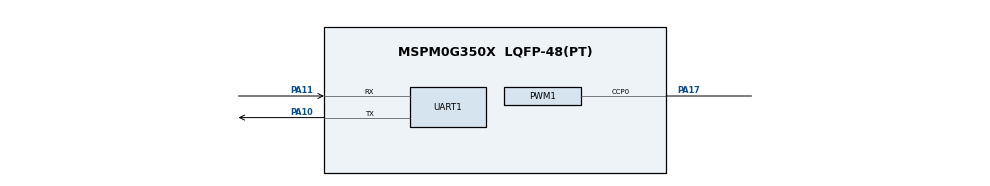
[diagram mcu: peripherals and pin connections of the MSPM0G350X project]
/**
 * @cliArgs --device "MSPM0G350X" --part "Default" --package "LQFP-48(PT)" --product "mspm0_sdk@2.10.00.04"
 * @versions {"tool":"1.27.1+4634"}
 */

/**
 * Import the modules used in this configuration.
 */
const GPIO   = scripting.addModule("/ti/driverlib/GPIO", {}, false);
const GPIO1  = GPIO.addInstance();
const GPIO3  = GPIO.addInstance();
const PWM    = scripting.addModule("/ti/driverlib/PWM", {}, false);
const PWM1   = PWM.addInstance();
const SYSCTL = scripting.addModule("/ti/driverlib/SYSCTL");
const UART   = scripting.addModule("/ti/driverlib/UART", {}, false);
const UART1  = UART.addInstance();

/**
 * Write custom configuration values to the imported modules.
 */
const gate7  = system.clockTree["MFCLKGATE"];
gate7.enable = true;

GPIO1.$name                          = "TB6612";
GPIO1.associatedPins.create(4);
GPIO1.associatedPins[0].$name        = "AIN1";
GPIO1.associatedPins[0].initialValue = "SET";
GPIO1.associatedPins[0].assignedPort = "PORTB";
GPIO1.associatedPins[0].assignedPin  = "18";
GPIO1.associatedPins[1].$name        = "AIN2";
GPIO1.associatedPins[1].initialValue = "SET";
GPIO1.associatedPins[1].assignedPort = "PORTA";
GPIO1.associatedPins[1].assignedPin  = "18 ";
GPIO1.associatedPins[2].$name        = "BIN1";
GPIO1.associatedPins[2].initialValue = "SET";
GPIO1.associatedPins[2].assignedPort = "PORTA";
GPIO1.associatedPins[2].assignedPin  = "12";
GPIO1.associatedPins[3].$name        = "BIN2";
GPIO1.associatedPins[3].initialValue = "SET";
GPIO1.associatedPins[3].assignedPort = "PORTA";
GPIO1.associatedPins[3].assignedPin  = "13";

const Board = scripting.addModule("/ti/driverlib/Board", {}, false);

GPIO3.$name                          = "OLED";
GPIO3.associatedPins.create(2);
GPIO3.associatedPins[0].$name        = "OLED_SCL";
GPIO3.associatedPins[0].initialValue = "SET";
GPIO3.associatedPins[0].assignedPort = "PORTB";
GPIO3.associatedPins[0].assignedPin  = "2";
GPIO3.associatedPins[1].initialValue = "SET";
GPIO3.associatedPins[1].assignedPort = "PORTB";
GPIO3.associatedPins[1].assignedPin  = "3";
GPIO3.associatedPins[1].$name        = "OLED_SDA";

PWM1.$name                      = "PWM_0";
PWM1.clockDivider               = 8;
PWM1.timerStartTimer            = true;
PWM1.peripheral.$assign         = "TIMA1";
PWM1.peripheral.ccp0Pin.$assign = "PA17";
PWM1.PWM_CHANNEL_0.$name        = "ti_driverlib_pwm_PWMTimerCC0";
PWM1.PWM_CHANNEL_0.invert       = true;
PWM1.PWM_CHANNEL_1.$name        = "ti_driverlib_pwm_PWMTimerCC1";
PWM1.PWM_CHANNEL_1.invert       = true;
PWM1.ccp0PinConfig.$name        = "ti_driverlib_gpio_GPIOPinGeneric0";
PWM1.ccp1PinConfig.$name        = "ti_driverlib_gpio_GPIOPinGeneric1";

SYSCTL.forceDefaultClkConfig = true;
SYSCTL.clockTreeEn           = true;

UART1.$name                    = "UART_0";
UART1.uartClkSrc               = "MFCLK";
UART1.enabledInterrupts        = ["RX"];
UART1.peripheral.$assign       = "UART0";
UART1.peripheral.rxPin.$assign = "PA11";
UART1.peripheral.txPin.$assign = "PA10";
UART1.txPinConfig.$name        = "ti_driverlib_gpio_GPIOPinGeneric4";
UART1.rxPinConfig.$name        = "ti_driverlib_gpio_GPIOPinGeneric5";

const ProjectConfig              = scripting.addModule("/ti/project_config/ProjectConfig", {}, false);
ProjectConfig.migrationCondition = true;

/**
 * Pinmux solution for unlocked pins/peripherals. This ensures that minor changes to the automatic solver in a future
 * version of the tool will not impact the pinmux you originally saw.  These lines can be completely deleted in order to
 * re-solve from scratch.
 */
GPIO1.associatedPins[0].pin.$suggestSolution = "PB18";
GPIO1.associatedPins[1].pin.$suggestSolution = "PA18";
GPIO1.associatedPins[2].pin.$suggestSolution = "PA12";
GPIO1.associatedPins[3].pin.$suggestSolution = "PA13";
Board.peripheral.$suggestSolution            = "DEBUGSS";
Board.peripheral.swclkPin.$suggestSolution   = "PA20";
Board.peripheral.swdioPin.$suggestSolution   = "PA19";
GPIO3.associatedPins[0].pin.$suggestSolution = "PB2";
GPIO3.associatedPins[1].pin.$suggestSolution = "PB3";
PWM1.peripheral.ccp1Pin.$suggestSolution     = "PA16";
